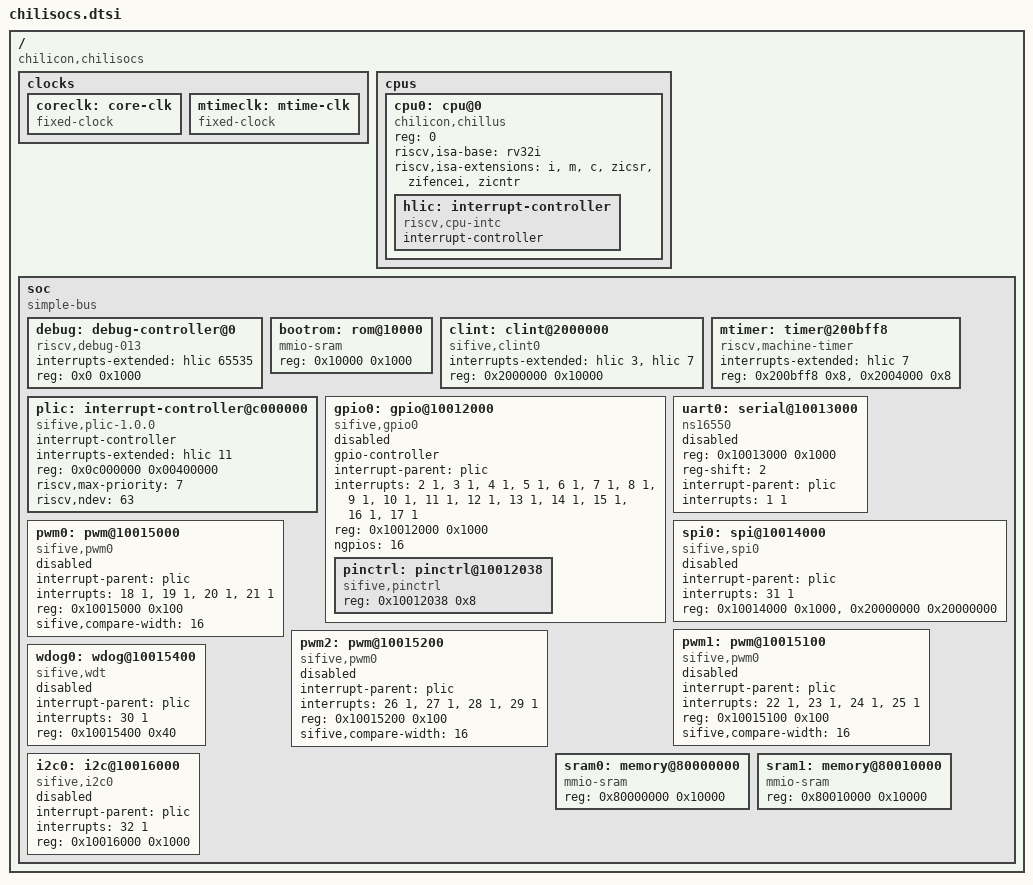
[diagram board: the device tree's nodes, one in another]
/* SPDX-License-Identifier: Apache-2.0 */
/* Copyright 2026 Chilicon */
/*
 * ChiliSoC-S :: chilisocs.dtsi -- the SoC for Zephyr (source/pkg/chilisocs_pkg.sv)
 *
 * Bases and PLIC sources as in chilisocs_pkg; every peripheral uses its
 * standard register layout (ns16550, SiFive CLINT / PLIC / GPIO / PWM / AON
 * watchdog / SPI, OpenCores I2C), so Zephyr's own drivers run it. A board
 * sets the clock frequencies (core-clk, and mtime-clk = core clock / socctl
 * clkdiv[0], reset value 2) and the console baud rate. The DMA (SiFive
 * PDMA layout) has no Zephyr driver and no node.
 */

#include <zephyr/dt-bindings/gpio/gpio.h>

/ {
	#address-cells = <1>;
	#size-cells = <1>;
	compatible = "chilicon,chilisocs";

	clocks {
		coreclk: core-clk {
			#clock-cells = <0>;
			compatible = "fixed-clock";
		};

		mtimeclk: mtime-clk {
			#clock-cells = <0>;
			compatible = "fixed-clock";
		};
	};

	cpus {
		#address-cells = <1>;
		#size-cells = <0>;

		cpu0: cpu@0 {
			compatible = "chilicon,chillus", "riscv";
			device_type = "cpu";
			reg = <0>;
			riscv,isa-base = "rv32i";
			riscv,isa-extensions = "i", "m", "c", "zicsr", "zifencei", "zicntr";
			status = "okay";

			hlic: interrupt-controller {
				compatible = "riscv,cpu-intc";
				#address-cells = <0>;
				#interrupt-cells = <1>;
				interrupt-controller;
			};
		};
	};

	soc {
		#address-cells = <1>;
		#size-cells = <1>;
		compatible = "simple-bus";
		ranges;

		debug: debug-controller@0 {
			compatible = "riscv,debug-013";
			interrupts-extended = <&hlic 65535>;
			reg = <0x0 0x1000>;
			reg-names = "control";
		};

		bootrom: rom@10000 {
			compatible = "mmio-sram";
			reg = <0x10000 0x1000>;
		};

		clint: clint@2000000 {
			compatible = "sifive,clint0";
			interrupts-extended = <&hlic 3>, <&hlic 7>;
			reg = <0x2000000 0x10000>;
		};

		mtimer: timer@200bff8 {
			compatible = "riscv,machine-timer";
			interrupts-extended = <&hlic 7>;
			reg = <0x200bff8 0x8>, <0x2004000 0x8>;
			reg-names = "mtime", "mtimecmp";
		};

		plic: interrupt-controller@c000000 {
			compatible = "sifive,plic-1.0.0";
			#address-cells = <0>;
			#interrupt-cells = <2>;
			interrupt-controller;
			interrupts-extended = <&hlic 11>;
			reg = <0x0c000000 0x00400000>;
			riscv,max-priority = <7>;
			riscv,ndev = <63>;
		};

		gpio0: gpio@10012000 {
			compatible = "sifive,gpio0";
			gpio-controller;
			interrupt-parent = <&plic>;
			interrupts = <2 1>, <3 1>, <4 1>, <5 1>,
				     <6 1>, <7 1>, <8 1>, <9 1>,
				     <10 1>, <11 1>, <12 1>, <13 1>,
				     <14 1>, <15 1>, <16 1>, <17 1>;
			reg = <0x10012000 0x1000>;
			reg-names = "control";
			ngpios = <16>;
			#gpio-cells = <2>;
			status = "disabled";

			#address-cells = <1>;
			#size-cells = <1>;
			ranges;

			pinctrl: pinctrl@10012038 {
				compatible = "sifive,pinctrl";
				reg = <0x10012038 0x8>;
			};
		};

		uart0: serial@10013000 {
			compatible = "ns16550";
			reg = <0x10013000 0x1000>;
			reg-shift = <2>;
			interrupt-parent = <&plic>;
			interrupts = <1 1>;
			status = "disabled";
		};

		spi0: spi@10014000 {
			compatible = "sifive,spi0";
			interrupt-parent = <&plic>;
			interrupts = <31 1>;
			reg = <0x10014000 0x1000>, <0x20000000 0x20000000>;
			reg-names = "control", "mem";
			#address-cells = <1>;
			#size-cells = <0>;
			status = "disabled";
		};

		pwm0: pwm@10015000 {
			compatible = "sifive,pwm0";
			interrupt-parent = <&plic>;
			interrupts = <18 1>, <19 1>, <20 1>, <21 1>;
			reg = <0x10015000 0x100>;
			reg-names = "control";
			sifive,compare-width = <16>;
			#pwm-cells = <2>;
			status = "disabled";
		};

		pwm1: pwm@10015100 {
			compatible = "sifive,pwm0";
			interrupt-parent = <&plic>;
			interrupts = <22 1>, <23 1>, <24 1>, <25 1>;
			reg = <0x10015100 0x100>;
			reg-names = "control";
			sifive,compare-width = <16>;
			#pwm-cells = <2>;
			status = "disabled";
		};

		pwm2: pwm@10015200 {
			compatible = "sifive,pwm0";
			interrupt-parent = <&plic>;
			interrupts = <26 1>, <27 1>, <28 1>, <29 1>;
			reg = <0x10015200 0x100>;
			reg-names = "control";
			sifive,compare-width = <16>;
			#pwm-cells = <2>;
			status = "disabled";
		};

		wdog0: wdog@10015400 {
			compatible = "sifive,wdt";
			interrupt-parent = <&plic>;
			interrupts = <30 1>;
			reg = <0x10015400 0x40>;
			reg-names = "control";
			status = "disabled";
		};

		i2c0: i2c@10016000 {
			compatible = "sifive,i2c0";
			interrupt-parent = <&plic>;
			interrupts = <32 1>;
			reg = <0x10016000 0x1000>;
			reg-names = "control";
			#address-cells = <1>;
			#size-cells = <0>;
			status = "disabled";
		};

		/* SRAM0: instruction and data buses (code) */
		sram0: memory@80000000 {
			compatible = "mmio-sram";
			reg = <0x80000000 0x10000>;
		};

		/* SRAM1: data bus only (data, stack) */
		sram1: memory@80010000 {
			compatible = "mmio-sram";
			reg = <0x80010000 0x10000>;
		};
	};
};
